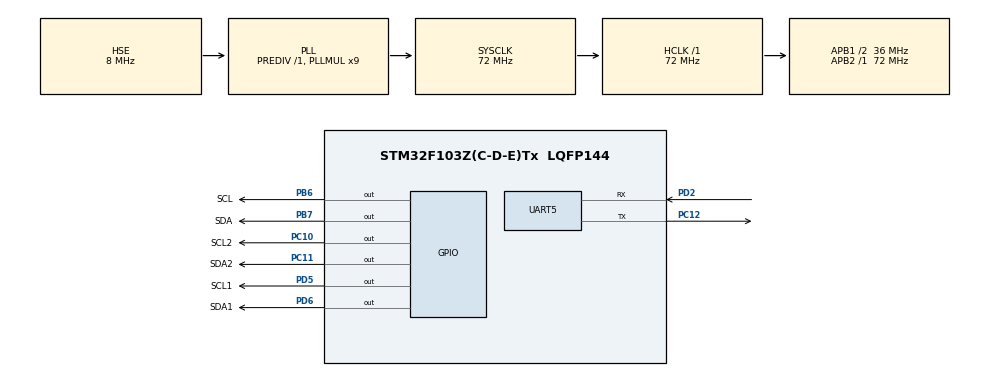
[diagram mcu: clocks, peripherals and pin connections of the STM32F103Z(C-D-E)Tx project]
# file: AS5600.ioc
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Mcu.Family=STM32F1
Mcu.Name=STM32F103Z(C-D-E)Tx
Mcu.Package=LQFP144
NVIC.PriorityGroup=NVIC_PRIORITYGROUP_4
NVIC.TIM2_IRQn=true\:0\:0\:false\:false\:true\:true\:true
OSC_IN.Mode=HSE-External-Oscillator
OSC_IN.Signal=RCC_OSC_IN
OSC_OUT.Mode=HSE-External-Oscillator
OSC_OUT.Signal=RCC_OSC_OUT
PA13.Mode=Serial_Wire
PA13.Signal=SYS_JTMS-SWDIO
PA14.Mode=Serial_Wire
PA14.Signal=SYS_JTCK-SWCLK
PB6.GPIO_Label=SCL
PB6.GPIO_Speed=GPIO_SPEED_FREQ_HIGH
PB6.Signal=GPIO_Output
PB7.GPIO_Label=SDA
PB7.GPIO_Speed=GPIO_SPEED_FREQ_HIGH
PB7.Signal=GPIO_Output
PC10.GPIO_Label=SCL2
PC10.GPIO_Speed=GPIO_SPEED_FREQ_HIGH
PC10.Signal=GPIO_Output
PC11.GPIO_Label=SDA2
PC11.GPIO_Speed=GPIO_SPEED_FREQ_HIGH
PC11.Signal=GPIO_Output
PC12.Mode=Asynchronous
PC12.Signal=UART5_TX
PD2.Mode=Asynchronous
PD2.Signal=UART5_RX
PD5.GPIO_Label=SCL1
PD5.GPIO_Speed=GPIO_SPEED_FREQ_HIGH
PD5.Signal=GPIO_Output
PD6.GPIO_Label=SDA1
PD6.GPIO_Speed=GPIO_SPEED_FREQ_HIGH
PD6.Signal=GPIO_Output
ProjectManager.HeapSize=0x200
ProjectManager.StackSize=0x400
ProjectManager.TargetToolchain=MDK-ARM V5.32
RCC.AHBFreq_Value=72000000
RCC.APB1CLKDivider=RCC_HCLK_DIV2
RCC.APB1Freq_Value=36000000
RCC.APB1TimFreq_Value=72000000
RCC.APB2Freq_Value=72000000
RCC.APB2TimFreq_Value=72000000
RCC.HCLKFreq_Value=72000000
RCC.PLLMUL=RCC_PLL_MUL9
RCC.PLLSourceVirtual=RCC_PLLSOURCE_HSE
RCC.SYSCLKFreq_VALUE=72000000
RCC.SYSCLKSource=RCC_SYSCLKSOURCE_PLLCLK
RCC.USBFreq_Value=72000000
TIM2.Period=1000-1
TIM2.Prescaler=72-1
UART5.VirtualMode=Asynchronous
VP_TIM2_VS_ClockSourceINT.Mode=Internal
board=custom

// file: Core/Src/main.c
/* USER CODE BEGIN Header */
/**
  ******************************************************************************
  * @file           : main.c
  * @brief          : Main program body
  ******************************************************************************
  * @attention
  *
  * Copyright (c) 2025 STMicroelectronics.
  * All rights reserved.
  *
  * This software is licensed under terms that can be found in the LICENSE file
  * in the root directory of this software component.
  * If no LICENSE file comes with this software, it is provided AS-IS.
  *
  ******************************************************************************
  */
/* USER CODE END Header */
#include "main.h"
#include "tim.h"
#include "usart.h"
#include "gpio.h"

/* USER CODE BEGIN Includes */
#include "AS5600_app.h"
/* USER CODE END Includes */

void SystemClock_Config(void);

int main(void)
{

  /* MCU Configuration--------------------------------------------------------*/

  /* Reset of all peripherals, Initializes the Flash interface and the Systick. */
  HAL_Init();

  /* Configure the system clock */
  SystemClock_Config();

  /* Initialize all configured peripherals */
  MX_GPIO_Init();
  MX_UART5_Init();
  MX_TIM2_Init();
  /* USER CODE BEGIN 2 */
	delay_init();
  as5600_init_all();
  delay_ms(10);
  HAL_TIM_Base_Start_IT(&htim2);

  /* USER CODE END 2 */

  /* Infinite loop */
  /* USER CODE BEGIN WHILE */

  while (1)
  {
    for (int i = 0; i < AS5600_DEVICE_COUNT; i++) {
      if (g_as5600_devices[i].angle_data.angle_flag) {
          g_as5600_devices[i].angle_data.angle_flag = 0;
          as5600_update_angle_data((AS5600_Device_Index_t) i);
          // 获取并打印数据
          float rpm = as5600_get_rpm((AS5600_Device_Index_t)i);
          int32_t turns = as5600_get_total_turns((AS5600_Device_Index_t)i);
          float angle = as5600_get_relative_angle((AS5600_Device_Index_t)i);

          // 使用统一的打印函数
          as5600_debug_print("Device[%d]: Angle=%.2f, RPM=%.2f, Turns=%ld\r\n",
                             i + 1, angle, rpm, turns);
      }
  }
  HAL_Delay(200);
  }
  /* USER CODE END 3 */
}

void SystemClock_Config(void)
{
  RCC_OscInitTypeDef RCC_OscInitStruct = {0};
  RCC_ClkInitTypeDef RCC_ClkInitStruct = {0};

  /** Initializes the RCC Oscillators according to the specified parameters
  * in the RCC_OscInitTypeDef structure.
  */
  RCC_OscInitStruct.OscillatorType = RCC_OSCILLATORTYPE_HSE;
  RCC_OscInitStruct.HSEState = RCC_HSE_ON;
  RCC_OscInitStruct.HSEPredivValue = RCC_HSE_PREDIV_DIV1;
  RCC_OscInitStruct.HSIState = RCC_HSI_ON;
  RCC_OscInitStruct.PLL.PLLState = RCC_PLL_ON;
  RCC_OscInitStruct.PLL.PLLSource = RCC_PLLSOURCE_HSE;
  RCC_OscInitStruct.PLL.PLLMUL = RCC_PLL_MUL9;
  if (HAL_RCC_OscConfig(&RCC_OscInitStruct) != HAL_OK)
  {
    Error_Handler();
  }
  /** Initializes the CPU, AHB and APB buses clocks
  */
  RCC_ClkInitStruct.ClockType = RCC_CLOCKTYPE_HCLK|RCC_CLOCKTYPE_SYSCLK
                              |RCC_CLOCKTYPE_PCLK1|RCC_CLOCKTYPE_PCLK2;
  RCC_ClkInitStruct.SYSCLKSource = RCC_SYSCLKSOURCE_PLLCLK;
  RCC_ClkInitStruct.AHBCLKDivider = RCC_SYSCLK_DIV1;
  RCC_ClkInitStruct.APB1CLKDivider = RCC_HCLK_DIV2;
  RCC_ClkInitStruct.APB2CLKDivider = RCC_HCLK_DIV1;

  if (HAL_RCC_ClockConfig(&RCC_ClkInitStruct, FLASH_LATENCY_2) != HAL_OK)
  {
    Error_Handler();
  }
}

void Error_Handler(void)
{
  __disable_irq();
  while (1)
  {
  }
}
